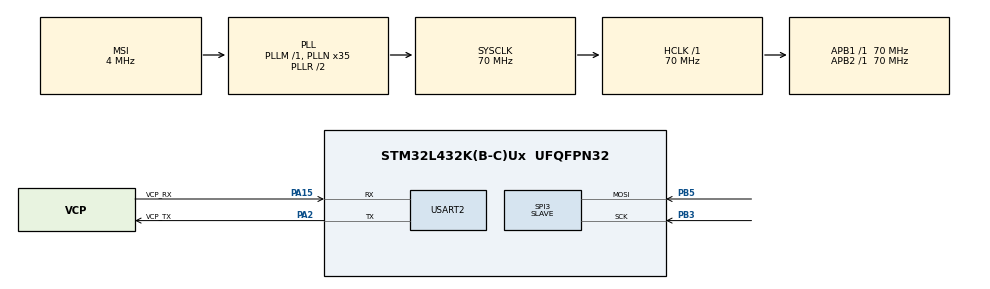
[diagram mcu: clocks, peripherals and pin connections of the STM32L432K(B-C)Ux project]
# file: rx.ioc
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Dma.Request0=SPI3_RX
Dma.SPI3_RX.0.Direction=DMA_PERIPH_TO_MEMORY
Dma.SPI3_RX.0.Instance=DMA2_Channel1
Dma.SPI3_RX.0.MemDataAlignment=DMA_MDATAALIGN_BYTE
Dma.SPI3_RX.0.MemInc=DMA_MINC_ENABLE
Dma.SPI3_RX.0.Mode=DMA_CIRCULAR
Dma.SPI3_RX.0.PeriphDataAlignment=DMA_PDATAALIGN_BYTE
Dma.SPI3_RX.0.PeriphInc=DMA_PINC_DISABLE
Dma.SPI3_RX.0.Priority=DMA_PRIORITY_LOW
Mcu.Family=STM32L4
Mcu.Name=STM32L432K(B-C)Ux
Mcu.Package=UFQFPN32
NVIC.DMA2_Channel1_IRQn=true\:0\:0\:false\:false\:true\:false\:true\:true
NVIC.PriorityGroup=NVIC_PRIORITYGROUP_4
NVIC.USART2_IRQn=true\:0\:0\:false\:false\:true\:true\:true\:true
PA0.GPIO_Label=MCO [High speed clock in]
PA0.Mode=HSE-External-Clock-Source-for-LittleOrca
PA0.Signal=RCC_CK_IN
PA13\ (JTMS-SWDIO).GPIO_Label=SWDIO
PA13\ (JTMS-SWDIO).Mode=Serial_Wire
PA13\ (JTMS-SWDIO).Signal=SYS_JTMS-SWDIO
PA14\ (JTCK-SWCLK).GPIO_Label=SWCLK
PA14\ (JTCK-SWCLK).Mode=Serial_Wire
PA14\ (JTCK-SWCLK).Signal=SYS_JTCK-SWCLK
PA15\ (JTDI).GPIO_Label=VCP_RX
PA15\ (JTDI).Mode=Asynchronous
PA15\ (JTDI).Signal=USART2_RX
PA2.GPIO_Label=VCP_TX
PA2.Mode=Asynchronous
PA2.Signal=USART2_TX
PB3\ (JTDO-TRACESWO).Mode=RX_Only_Simplex_Unidirect_Slave
PB3\ (JTDO-TRACESWO).Signal=SPI3_SCK
PB5.Mode=RX_Only_Simplex_Unidirect_Slave
PB5.Signal=SPI3_MOSI
PC14-OSC32_IN\ (PC14).Mode=LSE-External-Oscillator
PC14-OSC32_IN\ (PC14).Signal=RCC_OSC32_IN
PC15-OSC32_OUT\ (PC15).Mode=LSE-External-Oscillator
PC15-OSC32_OUT\ (PC15).Signal=RCC_OSC32_OUT
ProjectManager.HeapSize=0x200
ProjectManager.StackSize=0x400
ProjectManager.TargetToolchain=STM32CubeIDE
RCC.AHBFreq_Value=70000000
RCC.APB1Freq_Value=70000000
RCC.APB1TimFreq_Value=70000000
RCC.APB2Freq_Value=70000000
RCC.APB2TimFreq_Value=70000000
RCC.CortexFreq_Value=70000000
RCC.HCLKFreq_Value=70000000
RCC.HSE_VALUE=8000000
RCC.HSI16_VALUE=16000000
RCC.HSI48_VALUE=48000000
RCC.HSI_VALUE=16000000
RCC.MSI_VALUE=4000000
RCC.PLLMUL=RCC_PLLMUL_4
RCC.PLLN=35
RCC.SYSCLKFreq_VALUE=70000000
RCC.SYSCLKSource=RCC_SYSCLKSOURCE_PLLCLK
RCC.VCOOutputFreq_Value=140000000
SPI3.DataSize=SPI_DATASIZE_8BIT
SPI3.Direction=SPI_DIRECTION_2LINES_RXONLY
SPI3.Mode=SPI_MODE_SLAVE
SPI3.VirtualType=VM_SLAVE
USART2.VirtualMode-Asynchronous=VM_ASYNC
board=NUCLEO-L432KC

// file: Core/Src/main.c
/* USER CODE BEGIN Header */
/**
  ******************************************************************************
  * @file           : main.c
  * @brief          : Main program body
  ******************************************************************************
  * @attention
  *
  * Copyright (c) 2024 STMicroelectronics.
  * All rights reserved.
  *
  * This software is licensed under terms that can be found in the LICENSE file
  * in the root directory of this software component.
  * If no LICENSE file comes with this software, it is provided AS-IS.
  *
  ******************************************************************************
  */
/* USER CODE END Header */
#include "main.h"

/* USER CODE BEGIN Includes */
#include <stdio.h>
#include <string.h>
/* USER CODE END Includes */

/* USER CODE BEGIN PD */
#define BUFFER_SIZE 32

/* USER CODE END PD */

SPI_HandleTypeDef hspi3;
DMA_HandleTypeDef hdma_spi3_rx;

UART_HandleTypeDef huart2;

/* USER CODE BEGIN PV */
uint8_t RX_Buffer[BUFFER_SIZE] = {0};
char tick[] = ".\r\n";
/* USER CODE END PV */

void SystemClock_Config(void);
static void MX_GPIO_Init(void);
static void MX_DMA_Init(void);
static void MX_USART2_UART_Init(void);
static void MX_SPI3_Init(void);
/* USER CODE BEGIN PFP */
static void UART_Print(char* str)
{
	HAL_UART_Transmit(&huart2, (uint8_t *) str, strlen(str), 100);
}
/* USER CODE END PFP */

int main(void)
{

  /* MCU Configuration--------------------------------------------------------*/

  /* Reset of all peripherals, Initializes the Flash interface and the Systick. */
  HAL_Init();

  /* Configure the system clock */
  SystemClock_Config();

  /* Initialize all configured peripherals */
  MX_GPIO_Init();
  MX_DMA_Init();
  MX_USART2_UART_Init();
  MX_SPI3_Init();
  /* USER CODE BEGIN 2 */
  HAL_SPI_Receive_DMA(&hspi3, RX_Buffer, BUFFER_SIZE);

  /* USER CODE END 2 */

  /* Infinite loop */
  while (1)
  {

    /* USER CODE BEGIN 3 */
    HAL_SPI_Receive_DMA(&hspi3, RX_Buffer, BUFFER_SIZE);
    //UART_Print(tick);
    //uint8_t RX_Buffer[BUFFER_SIZE]={0};
  }
  /* USER CODE END 3 */
}

void SystemClock_Config(void)
{
  RCC_OscInitTypeDef RCC_OscInitStruct = {0};
  RCC_ClkInitTypeDef RCC_ClkInitStruct = {0};

  /** Configure the main internal regulator output voltage
  */
  if (HAL_PWREx_ControlVoltageScaling(PWR_REGULATOR_VOLTAGE_SCALE1) != HAL_OK)
  {
    Error_Handler();
  }

  /** Configure LSE Drive Capability
  */
  HAL_PWR_EnableBkUpAccess();
  __HAL_RCC_LSEDRIVE_CONFIG(RCC_LSEDRIVE_LOW);

  /** Initializes the RCC Oscillators according to the specified parameters
  * in the RCC_OscInitTypeDef structure.
  */
  RCC_OscInitStruct.OscillatorType = RCC_OSCILLATORTYPE_LSE|RCC_OSCILLATORTYPE_MSI;
  RCC_OscInitStruct.LSEState = RCC_LSE_ON;
  RCC_OscInitStruct.MSIState = RCC_MSI_ON;
  RCC_OscInitStruct.MSICalibrationValue = 0;
  RCC_OscInitStruct.MSIClockRange = RCC_MSIRANGE_6;
  RCC_OscInitStruct.PLL.PLLState = RCC_PLL_ON;
  RCC_OscInitStruct.PLL.PLLSource = RCC_PLLSOURCE_MSI;
  RCC_OscInitStruct.PLL.PLLM = 1;
  RCC_OscInitStruct.PLL.PLLN = 35;
  RCC_OscInitStruct.PLL.PLLP = RCC_PLLP_DIV7;
  RCC_OscInitStruct.PLL.PLLQ = RCC_PLLQ_DIV2;
  RCC_OscInitStruct.PLL.PLLR = RCC_PLLR_DIV2;
  if (HAL_RCC_OscConfig(&RCC_OscInitStruct) != HAL_OK)
  {
    Error_Handler();
  }

  /** Initializes the CPU, AHB and APB buses clocks
  */
  RCC_ClkInitStruct.ClockType = RCC_CLOCKTYPE_HCLK|RCC_CLOCKTYPE_SYSCLK
                              |RCC_CLOCKTYPE_PCLK1|RCC_CLOCKTYPE_PCLK2;
  RCC_ClkInitStruct.SYSCLKSource = RCC_SYSCLKSOURCE_PLLCLK;
  RCC_ClkInitStruct.AHBCLKDivider = RCC_SYSCLK_DIV1;
  RCC_ClkInitStruct.APB1CLKDivider = RCC_HCLK_DIV1;
  RCC_ClkInitStruct.APB2CLKDivider = RCC_HCLK_DIV1;

  if (HAL_RCC_ClockConfig(&RCC_ClkInitStruct, FLASH_LATENCY_4) != HAL_OK)
  {
    Error_Handler();
  }

  /** Enable MSI Auto calibration
  */
  HAL_RCCEx_EnableMSIPLLMode();
}

static void MX_SPI3_Init(void)
{

  /* SPI3 parameter configuration*/
  hspi3.Instance = SPI3;
  hspi3.Init.Mode = SPI_MODE_SLAVE;
  hspi3.Init.Direction = SPI_DIRECTION_2LINES_RXONLY;
  hspi3.Init.DataSize = SPI_DATASIZE_8BIT;
  hspi3.Init.CLKPolarity = SPI_POLARITY_LOW;
  hspi3.Init.CLKPhase = SPI_PHASE_1EDGE;
  hspi3.Init.NSS = SPI_NSS_SOFT;
  hspi3.Init.FirstBit = SPI_FIRSTBIT_MSB;
  hspi3.Init.TIMode = SPI_TIMODE_DISABLE;
  hspi3.Init.CRCCalculation = SPI_CRCCALCULATION_DISABLE;
  hspi3.Init.CRCPolynomial = 7;
  hspi3.Init.CRCLength = SPI_CRC_LENGTH_DATASIZE;
  hspi3.Init.NSSPMode = SPI_NSS_PULSE_DISABLE;
  if (HAL_SPI_Init(&hspi3) != HAL_OK)
  {
    Error_Handler();
  }

}

static void MX_USART2_UART_Init(void)
{

  huart2.Instance = USART2;
  huart2.Init.BaudRate = 115200;
  huart2.Init.WordLength = UART_WORDLENGTH_8B;
  huart2.Init.StopBits = UART_STOPBITS_1;
  huart2.Init.Parity = UART_PARITY_NONE;
  huart2.Init.Mode = UART_MODE_TX_RX;
  huart2.Init.HwFlowCtl = UART_HWCONTROL_NONE;
  huart2.Init.OverSampling = UART_OVERSAMPLING_16;
  huart2.Init.OneBitSampling = UART_ONE_BIT_SAMPLE_DISABLE;
  huart2.AdvancedInit.AdvFeatureInit = UART_ADVFEATURE_NO_INIT;
  if (HAL_UART_Init(&huart2) != HAL_OK)
  {
    Error_Handler();
  }

}

static void MX_DMA_Init(void)
{

  /* DMA controller clock enable */
  __HAL_RCC_DMA2_CLK_ENABLE();

  /* DMA interrupt init */
  /* DMA2_Channel1_IRQn interrupt configuration */
  HAL_NVIC_SetPriority(DMA2_Channel1_IRQn, 0, 0);
  HAL_NVIC_EnableIRQ(DMA2_Channel1_IRQn);

}

static void MX_GPIO_Init(void)
{

  /* GPIO Ports Clock Enable */
  __HAL_RCC_GPIOC_CLK_ENABLE();
  __HAL_RCC_GPIOA_CLK_ENABLE();
  __HAL_RCC_GPIOB_CLK_ENABLE();

}

/* USER CODE BEGIN 4 */
void HAL_SPI_RxCpltCallback(SPI_HandleTypeDef * hspi)
{
    HAL_SPI_Receive_IT(&hspi3, RX_Buffer, BUFFER_SIZE);
    HAL_UART_Transmit_IT(&huart2, RX_Buffer, BUFFER_SIZE);
}
/* USER CODE END 4 */

void Error_Handler(void)
{
  __disable_irq();
  while (1)
  {
  }
}
